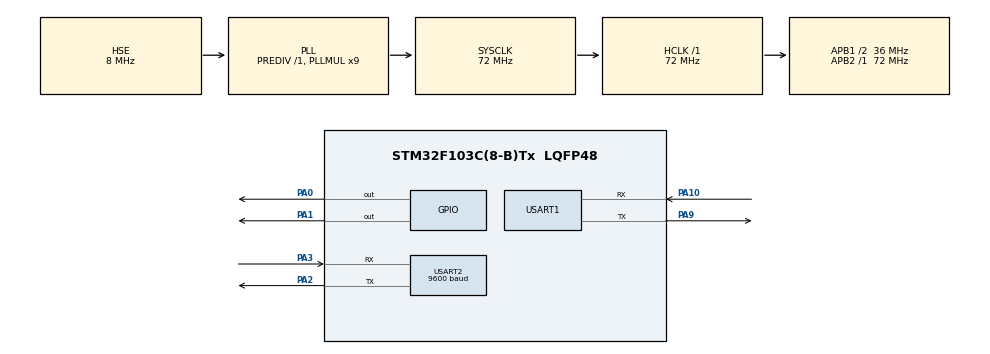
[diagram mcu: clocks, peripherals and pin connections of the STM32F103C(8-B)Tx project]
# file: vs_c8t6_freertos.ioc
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Dma.Request0=USART2_RX
Dma.Request1=USART2_TX
Dma.Request2=USART1_RX
Dma.Request3=USART1_TX
Dma.USART1_RX.2.Direction=DMA_PERIPH_TO_MEMORY
Dma.USART1_RX.2.Instance=DMA1_Channel5
Dma.USART1_RX.2.MemDataAlignment=DMA_MDATAALIGN_BYTE
Dma.USART1_RX.2.MemInc=DMA_MINC_ENABLE
Dma.USART1_RX.2.Mode=DMA_NORMAL
Dma.USART1_RX.2.PeriphDataAlignment=DMA_PDATAALIGN_BYTE
Dma.USART1_RX.2.PeriphInc=DMA_PINC_DISABLE
Dma.USART1_RX.2.Priority=DMA_PRIORITY_LOW
Dma.USART1_TX.3.Direction=DMA_MEMORY_TO_PERIPH
Dma.USART1_TX.3.Instance=DMA1_Channel4
Dma.USART1_TX.3.MemDataAlignment=DMA_MDATAALIGN_BYTE
Dma.USART1_TX.3.MemInc=DMA_MINC_ENABLE
Dma.USART1_TX.3.Mode=DMA_NORMAL
Dma.USART1_TX.3.PeriphDataAlignment=DMA_PDATAALIGN_BYTE
Dma.USART1_TX.3.PeriphInc=DMA_PINC_DISABLE
Dma.USART1_TX.3.Priority=DMA_PRIORITY_LOW
Dma.USART2_RX.0.Direction=DMA_PERIPH_TO_MEMORY
Dma.USART2_RX.0.Instance=DMA1_Channel6
Dma.USART2_RX.0.MemDataAlignment=DMA_MDATAALIGN_BYTE
Dma.USART2_RX.0.MemInc=DMA_MINC_ENABLE
Dma.USART2_RX.0.Mode=DMA_NORMAL
Dma.USART2_RX.0.PeriphDataAlignment=DMA_PDATAALIGN_BYTE
Dma.USART2_RX.0.PeriphInc=DMA_PINC_DISABLE
Dma.USART2_RX.0.Priority=DMA_PRIORITY_LOW
Dma.USART2_TX.1.Direction=DMA_MEMORY_TO_PERIPH
Dma.USART2_TX.1.Instance=DMA1_Channel7
Dma.USART2_TX.1.MemDataAlignment=DMA_MDATAALIGN_BYTE
Dma.USART2_TX.1.MemInc=DMA_MINC_ENABLE
Dma.USART2_TX.1.Mode=DMA_NORMAL
Dma.USART2_TX.1.PeriphDataAlignment=DMA_PDATAALIGN_BYTE
Dma.USART2_TX.1.PeriphInc=DMA_PINC_DISABLE
Dma.USART2_TX.1.Priority=DMA_PRIORITY_LOW
FREERTOS.Tasks01=LEDTask,24,128,StartLEDTask,Default,NULL,Dynamic,NULL,NULL;SerialTask,8,128,StartSerialTask,Default,NULL,Dynamic,NULL,NULL
Mcu.Family=STM32F1
Mcu.Name=STM32F103C(8-B)Tx
Mcu.Package=LQFP48
NVIC.DMA1_Channel4_IRQn=true\:5\:0\:false\:false\:true\:true\:false\:true\:true
NVIC.DMA1_Channel5_IRQn=true\:5\:0\:false\:false\:true\:true\:false\:true\:true
NVIC.DMA1_Channel6_IRQn=true\:5\:0\:false\:false\:true\:true\:false\:true\:true
NVIC.DMA1_Channel7_IRQn=true\:5\:0\:false\:false\:true\:true\:false\:true\:true
NVIC.PriorityGroup=NVIC_PRIORITYGROUP_4
NVIC.TIM4_IRQn=true\:15\:0\:false\:false\:true\:false\:false\:true\:true
NVIC.TimeBase=TIM4_IRQn
NVIC.TimeBaseIP=TIM4
NVIC.USART1_IRQn=true\:5\:0\:false\:false\:true\:true\:true\:true\:true
NVIC.USART2_IRQn=true\:5\:0\:false\:false\:true\:true\:true\:true\:true
PA0-WKUP.Signal=GPIO_Output
PA1.Signal=GPIO_Output
PA10.Mode=Asynchronous
PA10.Signal=USART1_RX
PA13.Mode=Serial_Wire
PA13.Signal=SYS_JTMS-SWDIO
PA14.Mode=Serial_Wire
PA14.Signal=SYS_JTCK-SWCLK
PA2.Mode=Asynchronous
PA2.Signal=USART2_TX
PA3.Mode=Asynchronous
PA3.Signal=USART2_RX
PA9.Mode=Asynchronous
PA9.Signal=USART1_TX
PD0-OSC_IN.Mode=HSE-External-Oscillator
PD0-OSC_IN.Signal=RCC_OSC_IN
PD1-OSC_OUT.Mode=HSE-External-Oscillator
PD1-OSC_OUT.Signal=RCC_OSC_OUT
ProjectManager.HeapSize=0x200
ProjectManager.StackSize=0x400
ProjectManager.TargetToolchain=CMake
RCC.AHBFreq_Value=72000000
RCC.APB1CLKDivider=RCC_HCLK_DIV2
RCC.APB1Freq_Value=36000000
RCC.APB1TimFreq_Value=72000000
RCC.APB2Freq_Value=72000000
RCC.APB2TimFreq_Value=72000000
RCC.HCLKFreq_Value=72000000
RCC.PLLMUL=RCC_PLL_MUL9
RCC.PLLSourceVirtual=RCC_PLLSOURCE_HSE
RCC.SYSCLKFreq_VALUE=72000000
RCC.SYSCLKSource=RCC_SYSCLKSOURCE_PLLCLK
RCC.USBFreq_Value=72000000
STMicroelectronics.X-CUBE-ALGOBUILD.1.4.0.LibraryCcDSPOoLibraryJjDSPOoLibrary=true
USART1.VirtualMode=VM_ASYNC
USART2.BaudRate=9600
USART2.VirtualMode=VM_ASYNC
VP_FREERTOS_VS_CMSIS_V2.Mode=CMSIS_V2
VP_STMicroelectronics.X-CUBE-ALGOBUILD_VS_DSPOoLibraryJjLibrary_1.4.0_1.4.0.Mode=DSPOoLibraryJjLibrary
VP_SYS_VS_tim4.Mode=TIM4
board=custom

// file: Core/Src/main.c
/* USER CODE BEGIN Header */
/**
  ******************************************************************************
  * @file           : main.c
  * @brief          : Main program body
  ******************************************************************************
  * @attention
  *
  * Copyright (c) 2026 STMicroelectronics.
  * All rights reserved.
  *
  * This software is licensed under terms that can be found in the LICENSE file
  * in the root directory of this software component.
  * If no LICENSE file comes with this software, it is provided AS-IS.
  *
  ******************************************************************************
  */
/* USER CODE END Header */
#include "main.h"
#include "cmsis_os.h"
#include "dma.h"
#include "usart.h"
#include "gpio.h"

void SystemClock_Config(void);
void MX_FREERTOS_Init(void);

int main(void)
{

  /* MCU Configuration--------------------------------------------------------*/

  /* Reset of all peripherals, Initializes the Flash interface and the Systick. */
  HAL_Init();

  /* Configure the system clock */
  SystemClock_Config();

  /* Initialize all configured peripherals */
  MX_GPIO_Init();
  MX_DMA_Init();
  MX_USART2_UART_Init();
  MX_USART1_UART_Init();

  /* Init scheduler */
  osKernelInitialize();  /* Call init function for freertos objects (in cmsis_os2.c) */
  MX_FREERTOS_Init();

  /* Start scheduler */
  osKernelStart();

  /* We should never get here as control is now taken by the scheduler */

  /* Infinite loop */
  while (1)
  {

  }
}

void SystemClock_Config(void)
{
  RCC_OscInitTypeDef RCC_OscInitStruct = {0};
  RCC_ClkInitTypeDef RCC_ClkInitStruct = {0};

  /** Initializes the RCC Oscillators according to the specified parameters
  * in the RCC_OscInitTypeDef structure.
  */
  RCC_OscInitStruct.OscillatorType = RCC_OSCILLATORTYPE_HSE;
  RCC_OscInitStruct.HSEState = RCC_HSE_ON;
  RCC_OscInitStruct.HSEPredivValue = RCC_HSE_PREDIV_DIV1;
  RCC_OscInitStruct.HSIState = RCC_HSI_ON;
  RCC_OscInitStruct.PLL.PLLState = RCC_PLL_ON;
  RCC_OscInitStruct.PLL.PLLSource = RCC_PLLSOURCE_HSE;
  RCC_OscInitStruct.PLL.PLLMUL = RCC_PLL_MUL9;
  if (HAL_RCC_OscConfig(&RCC_OscInitStruct) != HAL_OK)
  {
    Error_Handler();
  }

  /** Initializes the CPU, AHB and APB buses clocks
  */
  RCC_ClkInitStruct.ClockType = RCC_CLOCKTYPE_HCLK|RCC_CLOCKTYPE_SYSCLK
                              |RCC_CLOCKTYPE_PCLK1|RCC_CLOCKTYPE_PCLK2;
  RCC_ClkInitStruct.SYSCLKSource = RCC_SYSCLKSOURCE_PLLCLK;
  RCC_ClkInitStruct.AHBCLKDivider = RCC_SYSCLK_DIV1;
  RCC_ClkInitStruct.APB1CLKDivider = RCC_HCLK_DIV2;
  RCC_ClkInitStruct.APB2CLKDivider = RCC_HCLK_DIV1;

  if (HAL_RCC_ClockConfig(&RCC_ClkInitStruct, FLASH_LATENCY_2) != HAL_OK)
  {
    Error_Handler();
  }
}

void HAL_TIM_PeriodElapsedCallback(TIM_HandleTypeDef *htim)
{
  if (htim->Instance == TIM4)
  {
    HAL_IncTick();
  }
}

void Error_Handler(void)
{
  __disable_irq();
  while (1)
  {
  }
}

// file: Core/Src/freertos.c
/* USER CODE BEGIN Header */
/**
  ******************************************************************************
  * File Name          : freertos.c
  * Description        : Code for freertos applications
  ******************************************************************************
  * @attention
  *
  * Copyright (c) 2026 STMicroelectronics.
  * All rights reserved.
  *
  * This software is licensed under terms that can be found in the LICENSE file
  * in the root directory of this software component.
  * If no LICENSE file comes with this software, it is provided AS-IS.
  *
  ******************************************************************************
  */
/* USER CODE END Header */

#include "FreeRTOS.h"
#include "task.h"
#include "main.h"
#include "cmsis_os.h"

/* USER CODE BEGIN Includes */

#include "usart.h"
#include "arm_math.h"

/* USER CODE END Includes */

/* Definitions for LEDTask */
osThreadId_t LEDTaskHandle;
const osThreadAttr_t LEDTask_attributes = {
  .name = "LEDTask",
  .stack_size = 128 * 4,
  .priority = (osPriority_t) osPriorityNormal,
};
/* Definitions for SerialTask */
osThreadId_t SerialTaskHandle;
const osThreadAttr_t SerialTask_attributes = {
  .name = "SerialTask",
  .stack_size = 128 * 4,
  .priority = (osPriority_t) osPriorityLow,
};

void StartLEDTask(void *argument);
void StartSerialTask(void *argument);

void MX_FREERTOS_Init(void); /* (MISRA C 2004 rule 8.1) */

void MX_FREERTOS_Init(void) {

  /* Create the thread(s) */
  /* creation of LEDTask */
  LEDTaskHandle = osThreadNew(StartLEDTask, NULL, &LEDTask_attributes);

  /* creation of SerialTask */
  SerialTaskHandle = osThreadNew(StartSerialTask, NULL, &SerialTask_attributes);

}

void StartLEDTask(void *argument)
{
  /* USER CODE BEGIN StartLEDTask */
  uint16_t counter = 0;
  /* Infinite loop */
  for(;;)
  {
    HAL_GPIO_TogglePin(GPIOA, GPIO_PIN_0);
    HAL_GPIO_WritePin(GPIOA, GPIO_PIN_1, GPIO_PIN_SET);
    osDelay(200);
    counter++;
  }
  /* USER CODE END StartLEDTask */
}

void StartSerialTask(void *argument)
{
  /* USER CODE BEGIN StartSerialTask */
  char msg[] = "Hello from FreeRTOS Serial Task!\r\n";
  char data[32];
  uint8_t counter = 0;
  /* Infinite loop */
  for(;;)
  {
    counter++;
    //HAL_UART_Transmit_DMA(&huart1, (uint8_t*)msg, sizeof(msg) - 1);
    //HAL_UART_Transmit_DMA(&huart1, (uint8_t*)&counter, sizeof(counter));
    snprintf(data, sizeof(data), "Counter: %d\r\n", counter);
    HAL_UART_Transmit_DMA(&huart1, (uint8_t*)data, strlen(data));
    osDelay(500);
  }
  /* USER CODE END StartSerialTask */
}
